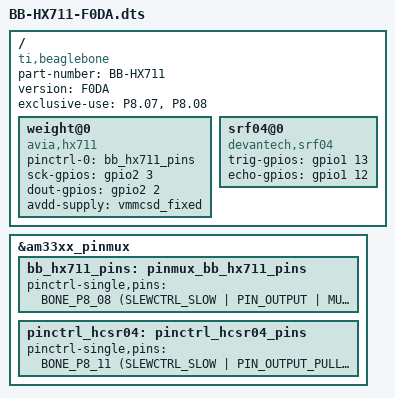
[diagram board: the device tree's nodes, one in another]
/dts-v1/;
/plugin/;

#include <dt-bindings/board/am335x-bbw-bbb-base.h>
#include <dt-bindings/gpio/gpio.h>
#include <dt-bindings/pinctrl/am33xx.h>

/ {
	compatible = "ti,beaglebone", "ti,beaglebone-black", "ti,beaglebone-green";


	/* identification */
	part-number = "BB-HX711";
	version = "F0DA";

	exclusive-use =
		/* the pin header uses */
		"P8.07",
		"P8.08";

	fragment@0 {
		target = <&am33xx_pinmux>;
		__overlay__ {
			bb_hx711_pins: pinmux_bb_hx711_pins {
				pinctrl-single,pins = <
					BONE_P8_08 (SLEWCTRL_SLOW | PIN_OUTPUT | MUX_MODE7) /* gpio2_3 */
					BONE_P8_07 (PIN_INPUT | MUX_MODE7) /* gpio2_2 */
				>;
			};                            

				pinctrl_hcsr04: pinctrl_hcsr04_pins {
					pinctrl-single,pins = <
                                        BONE_P8_11 (SLEWCTRL_SLOW | PIN_OUTPUT_PULLDOWN | MUX_MODE7) /* gpio1_13 */
                                        BONE_P8_12 (PIN_INPUT_PULLDOWN | MUX_MODE7) /* gpio1_12 */					
				>;
			};

                };
        };

        fragment@1 {
	        target-path="/";
		__overlay__ {
			weight@0 {
				pinctrl-names = "default";
				pinctrl-0 = <&bb_hx711_pins>;

	
				compatible = "avia,hx711";
				sck-gpios = <&gpio2 3 GPIO_ACTIVE_HIGH>;
				dout-gpios = <&gpio2 2 GPIO_ACTIVE_HIGH>;
				avdd-supply =  <&vmmcsd_fixed>;
			};
			srf04@0 {
				compatible = "devantech,srf04";
				trig-gpios = <&gpio1 13 GPIO_ACTIVE_HIGH>; /* P8_11 */
				echo-gpios = <&gpio1 12 GPIO_ACTIVE_HIGH>; /* P8_12 */
			};
                };
        };
};




